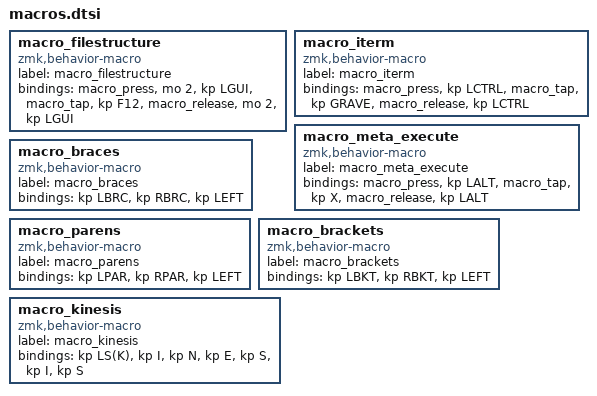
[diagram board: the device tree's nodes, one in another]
macro_filestructure: macro_filestructure{
compatible = "zmk,behavior-macro";
label = "macro_filestructure";
#binding-cells = <0>;
bindings = <&macro_press &mo 2 &kp LGUI>, <&macro_tap &kp F12>, <&macro_release &mo 2 &kp LGUI>;
};
macro_iterm: macro_iterm{
compatible = "zmk,behavior-macro";
label = "macro_iterm";
#binding-cells = <0>;
bindings = <&macro_press &kp LCTRL>, <&macro_tap &kp GRAVE>, <&macro_release &kp LCTRL>;
};
macro_meta_execute: macro_meta_execute{
compatible = "zmk,behavior-macro";
label = "macro_meta_execute";
#binding-cells = <0>;
bindings = <&macro_press &kp LALT>, <&macro_tap &kp X>, <&macro_release &kp LALT>;
};

macro_braces: macro_braces{
compatible = "zmk,behavior-macro";
label = "macro_braces";
#binding-cells = <0>;
bindings = <&kp LBRC>, <&kp RBRC>, <&kp LEFT>;
};
macro_parens: macro_parens{
compatible = "zmk,behavior-macro";
label = "macro_parens";
#binding-cells = <0>;
bindings = <&kp LPAR>, <&kp RPAR>, <&kp LEFT>;
};
macro_brackets: macro_brackets{
compatible = "zmk,behavior-macro";
label = "macro_brackets";
#binding-cells = <0>;
bindings = <&kp LBKT>, <&kp RBKT>, <&kp LEFT>;
};
macro_kinesis: macro_kinesis{
compatible = "zmk,behavior-macro";
label = "macro_kinesis";
#binding-cells = <0>;
bindings = <&kp LS(K)>, <&kp I>, <&kp N>, <&kp E>, <&kp S>, <&kp I>, <&kp S>;
};
